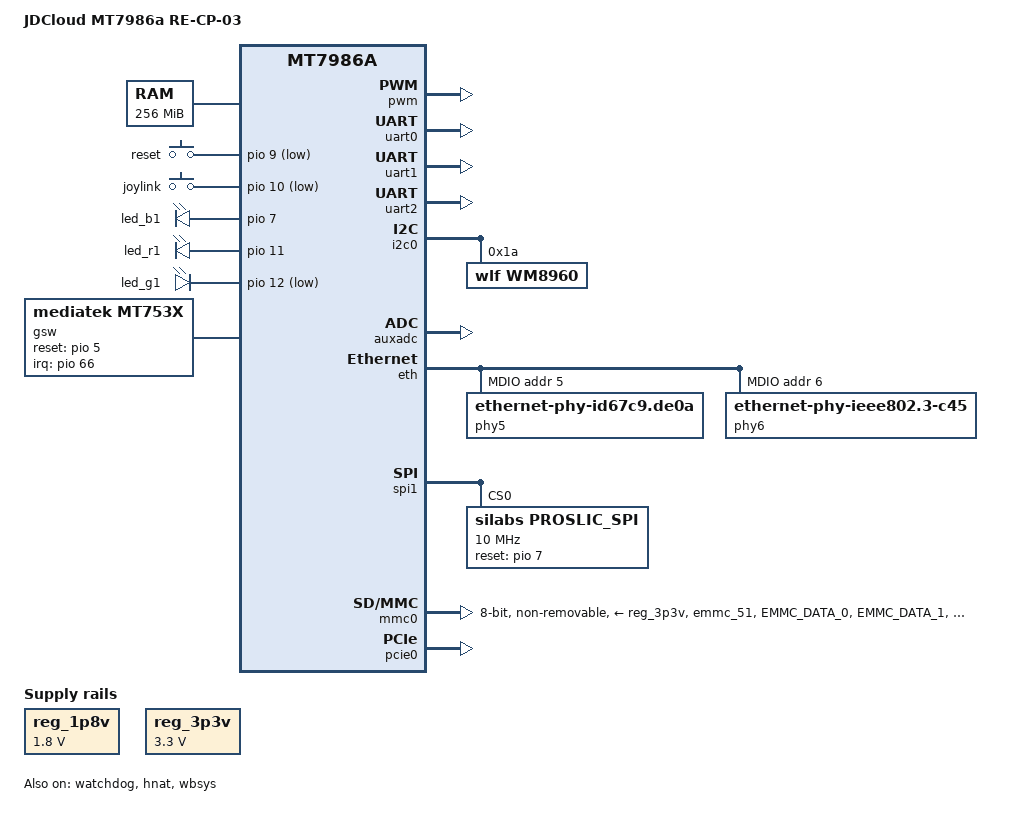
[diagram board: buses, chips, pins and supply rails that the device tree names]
/dts-v1/;
#include <dt-bindings/input/input.h>
#include <dt-bindings/gpio/gpio.h>
#include <dt-bindings/leds/common.h>
#include "mt7986a.dtsi"
#include "mt7986a-pinctrl.dtsi"
/ {
	model = "JDCloud MT7986a RE-CP-03";
	compatible = "mediatek,mt7986a-emmc-re-cp-03";

	aliases {
		led-boot = &red_power;
		led-failsafe = &red_power;
		led-upgrade = &blue_network;
		led-running = &green_plugin;
	};

	chosen {
		bootargs = "console=ttyS0,115200n1 loglevel=8  \
				earlycon=uart8250,mmio32,0x11002000 \
				root=PARTLABEL=rootfs rootwait rootfstype=squashfs,f2fs";
	};

	memory {
		reg = <0 0x40000000 0 0x10000000>;
	};

	reg_1p8v: regulator-1p8v {
		compatible = "regulator-fixed";
		regulator-name = "fixed-1.8V";
		regulator-min-microvolt = <1800000>;
		regulator-max-microvolt = <1800000>;
		regulator-boot-on;
		regulator-always-on;
	};

	reg_3p3v: regulator-3p3v {
		compatible = "regulator-fixed";
		regulator-name = "fixed-3.3V";
		regulator-min-microvolt = <3300000>;
		regulator-max-microvolt = <3300000>;
		regulator-boot-on;
		regulator-always-on;
	};

	sound_wm8960 {
		compatible = "mediatek,mt79xx-wm8960-machine";
		mediatek,platform = <&afe>;
		audio-routing = "Headphone", "HP_L",
				"Headphone", "HP_R",
				"LINPUT1", "AMIC",
				"RINPUT1", "AMIC";
		mediatek,audio-codec = <&wm8960>;
		status = "okay";
	};

	sound_si3218x {
		compatible = "mediatek,mt79xx-si3218x-machine";
		mediatek,platform = <&afe>;
		mediatek,ext-codec = <&proslic_spi>;
		status = "okay";
	};

	gpio-keys {
		compatible = "gpio-keys";

		reset {
			label = "reset";
			reg = <0x00>;
			gpios = <&pio 9 GPIO_ACTIVE_LOW>;
			linux,code = <KEY_RESTART>;
		};

		joylink {
			label = "joylink";
			reg = <0x00>;
			gpios = <&pio 10 GPIO_ACTIVE_LOW>;
			linux,code = <BTN_0>;
		};
	};

	leds {
		compatible = "gpio-leds";

		blue_network: blue {
			label = "led_b1";
			reg = <0x00>;
			gpios = <&pio 7 GPIO_ACTIVE_HIGH>;
			default-state = "off";
		};

		red_power: red {
			label = "led_r1";
			reg = <0x00>;
			gpios = <&pio 11 GPIO_ACTIVE_HIGH>;
			default-state = "on";
		};

		green_plugin: green {
			label = "led_g1";
			reg = <0x00>;
			gpios = <&pio 12 GPIO_ACTIVE_LOW>;
			default-state = "off";
		};
	};

	gsw: gsw@0 {
		compatible = "mediatek,mt753x";
		mediatek,ethsys = <&ethsys>;
		#address-cells = <1>;
		#size-cells = <0>;
	};
};

&fan {
	pwms = <&pwm 1 50000 0>;
	status = "disabled";
};

&pwm {
	pinctrl-names = "default";
	pinctrl-0 = <&pwm0_pin &pwm1_pin_g1>;
	status = "okay";
};

&uart0 {
	status = "okay";
};

&uart1 {
	pinctrl-names = "default";
	pinctrl-0 = <&uart1_pins>;
	status = "okay";
};

&uart2 {
	pinctrl-names = "default";
	pinctrl-0 = <&uart2_pins>;
	status = "okay";
};

&i2c0 {
	pinctrl-names = "default";
	pinctrl-0 = <&i2c_pins>;
	status = "okay";

	wm8960: wm8960@1a {
		compatible = "wlf,wm8960";
		reg = <0x1a>;
	};
};

&auxadc {
	status = "okay";
};

&watchdog {
	status = "okay";
};

&eth {
	status = "okay";

	gmac0: mac@0 {
		compatible = "mediatek,eth-mac";
		reg = <0>;
		phy-mode = "2500base-x";

		fixed-link {
			speed = <2500>;
			full-duplex;
			pause;
		};
	};

	gmac1: mac@1 {
		compatible = "mediatek,eth-mac";
		reg = <1>;
		phy-mode = "2500base-x";
		ext-phy-reset-gpios = <&pio 6 0>;

		fixed-link {
			speed = <2500>;
			full-duplex;
			pause;
		};
	};

	mdio: mdio-bus {
		#address-cells = <1>;
		#size-cells = <0>;

		phy5: phy@5 {
			compatible = "ethernet-phy-id67c9.de0a";
			reg = <5>;
		};

		phy6: phy@6 {
			compatible = "ethernet-phy-ieee802.3-c45";
			reg = <6>;
		};
	};
};

&gsw {
	mediatek,mdio = <&mdio>;
	mediatek,portmap = "lllll";
	mediatek,mdio_master_pinmux = <0>;
	reset-gpios = <&pio 5 0>;
	interrupt-parent = <&pio>;
	interrupts = <66 IRQ_TYPE_LEVEL_HIGH>;
	status = "okay";

	port5: port@5 {
		compatible = "mediatek,mt753x-port";
		reg = <5>;
		phy-mode = "sgmii";

		fixed-link {
			speed = <2500>;
			full-duplex;
		};
	};

	port6: port@6 {
		compatible = "mediatek,mt753x-port";
		mediatek,ssc-on;
		reg = <6>;
		phy-mode = "sgmii";
		fixed-link {
			speed = <2500>;
			full-duplex;
		};
	};
};


&hnat {
	mtketh-wan = "eth1";
	mtketh-lan = "eth0";
	mtketh-max-gmac = <2>;
	mtketh-ppe-num = <2>;
	status = "okay";
};

&spi1 {
	pinctrl-names = "default";
	pinctrl-0 = <&spic_pins_g2>;
	status = "okay";

	proslic_spi: proslic_spi@0 {
		compatible = "silabs,proslic_spi";
		reg = <0>;
		spi-max-frequency = <10000000>;
		spi-cpha = <1>;
		spi-cpol = <1>;
		channel_count = <1>;
		debug_level = <4>;       /* 1 = TRC, 2 = DBG, 4 = ERR */
		reset_gpio = <&pio 7 0>;
		ig,enable-spi = <1>;     /* 1: Enable, 0: Disable */
	};
};

&mmc0 {
	pinctrl-names = "default", "state_uhs";
	pinctrl-0 = <&mmc0_pins_default>;
	pinctrl-1 = <&mmc0_pins_uhs>;
	bus-width = <8>;
	max-frequency = <200000000>;
	cap-mmc-highspeed;
	mmc-hs200-1_8v;
	mmc-hs400-1_8v;
	hs400-ds-delay = <0x14014>;
	vmmc-supply = <&reg_3p3v>;
	vqmmc-supply = <&reg_1p8v>;
	non-removable;
	no-sd;
	no-sdio;
	status = "okay";
};

&pcie0 {
	pinctrl-names = "default";
	pinctrl-0 = <&pcie0_pins>;
	status = "okay";
};

&wbsys {
	status = "okay";
};

&pio {
	mmc0_pins_default: mmc0-pins-50-to-61-default {
		mux {
			function = "flash";
			groups = "emmc_51";
		};
		conf-cmd-dat {
			pins = "EMMC_DATA_0", "EMMC_DATA_1", "EMMC_DATA_2",
			       "EMMC_DATA_3", "EMMC_DATA_4", "EMMC_DATA_5",
			       "EMMC_DATA_6", "EMMC_DATA_7", "EMMC_CMD";
			input-enable;
			drive-strength = <MTK_DRIVE_4mA>;
			mediatek,pull-up-adv = <1>;	/* pull-up 10K */
		};
		conf-clk {
			pins = "EMMC_CK";
			drive-strength = <MTK_DRIVE_6mA>;
			mediatek,pull-down-adv = <2>;	/* pull-down 50K */
		};
		conf-ds {
			pins = "EMMC_DSL";
			mediatek,pull-down-adv = <2>;	/* pull-down 50K */
		};
		conf-rst {
			pins = "EMMC_RSTB";
			drive-strength = <MTK_DRIVE_4mA>;
			mediatek,pull-up-adv = <1>;	/* pull-up 10K */
		};
	};

	mmc0_pins_uhs: mmc0-pins-50-to-61-uhs {
		mux {
			function = "flash";
			groups = "emmc_51";
		};
		conf-cmd-dat {
			pins = "EMMC_DATA_0", "EMMC_DATA_1", "EMMC_DATA_2",
			       "EMMC_DATA_3", "EMMC_DATA_4", "EMMC_DATA_5",
			       "EMMC_DATA_6", "EMMC_DATA_7", "EMMC_CMD";
			input-enable;
			drive-strength = <MTK_DRIVE_4mA>;
			mediatek,pull-up-adv = <1>;	/* pull-up 10K */
		};
		conf-clk {
			pins = "EMMC_CK";
			drive-strength = <MTK_DRIVE_6mA>;
			mediatek,pull-down-adv = <2>;	/* pull-down 50K */
		};
		conf-ds {
			pins = "EMMC_DSL";
			mediatek,pull-down-adv = <2>;	/* pull-down 50K */
		};
		conf-rst {
			pins = "EMMC_RSTB";
			drive-strength = <MTK_DRIVE_4mA>;
			mediatek,pull-up-adv = <1>;	/* pull-up 10K */
		};
	};

	wf_2g_5g_pins: wf_2g_5g-pins {
		mux {
			function = "wifi";
			groups = "wf_2g", "wf_5g";
		};
		conf {
			pins = "WF0_HB1", "WF0_HB2", "WF0_HB3", "WF0_HB4",
			       "WF0_HB0", "WF0_HB0_B", "WF0_HB5", "WF0_HB6",
			       "WF0_HB7", "WF0_HB8", "WF0_HB9", "WF0_HB10",
			       "WF0_TOP_CLK", "WF0_TOP_DATA", "WF1_HB1",
			       "WF1_HB2", "WF1_HB3", "WF1_HB4", "WF1_HB0",
			       "WF1_HB5", "WF1_HB6", "WF1_HB7", "WF1_HB8",
			       "WF1_TOP_CLK", "WF1_TOP_DATA";
			drive-strength = <MTK_DRIVE_4mA>;
		};
	};

	wf_dbdc_pins: wf_dbdc-pins {
		mux {
			function = "wifi";
			groups = "wf_dbdc";
		};
		conf {
			pins = "WF0_HB1", "WF0_HB2", "WF0_HB3", "WF0_HB4",
			       "WF0_HB0", "WF0_HB0_B", "WF0_HB5", "WF0_HB6",
			       "WF0_HB7", "WF0_HB8", "WF0_HB9", "WF0_HB10",
			       "WF0_TOP_CLK", "WF0_TOP_DATA", "WF1_HB1",
			       "WF1_HB2", "WF1_HB3", "WF1_HB4", "WF1_HB0",
			       "WF1_HB5", "WF1_HB6", "WF1_HB7", "WF1_HB8",
			       "WF1_TOP_CLK", "WF1_TOP_DATA";
			drive-strength = <MTK_DRIVE_4mA>;
		};
	};
};
